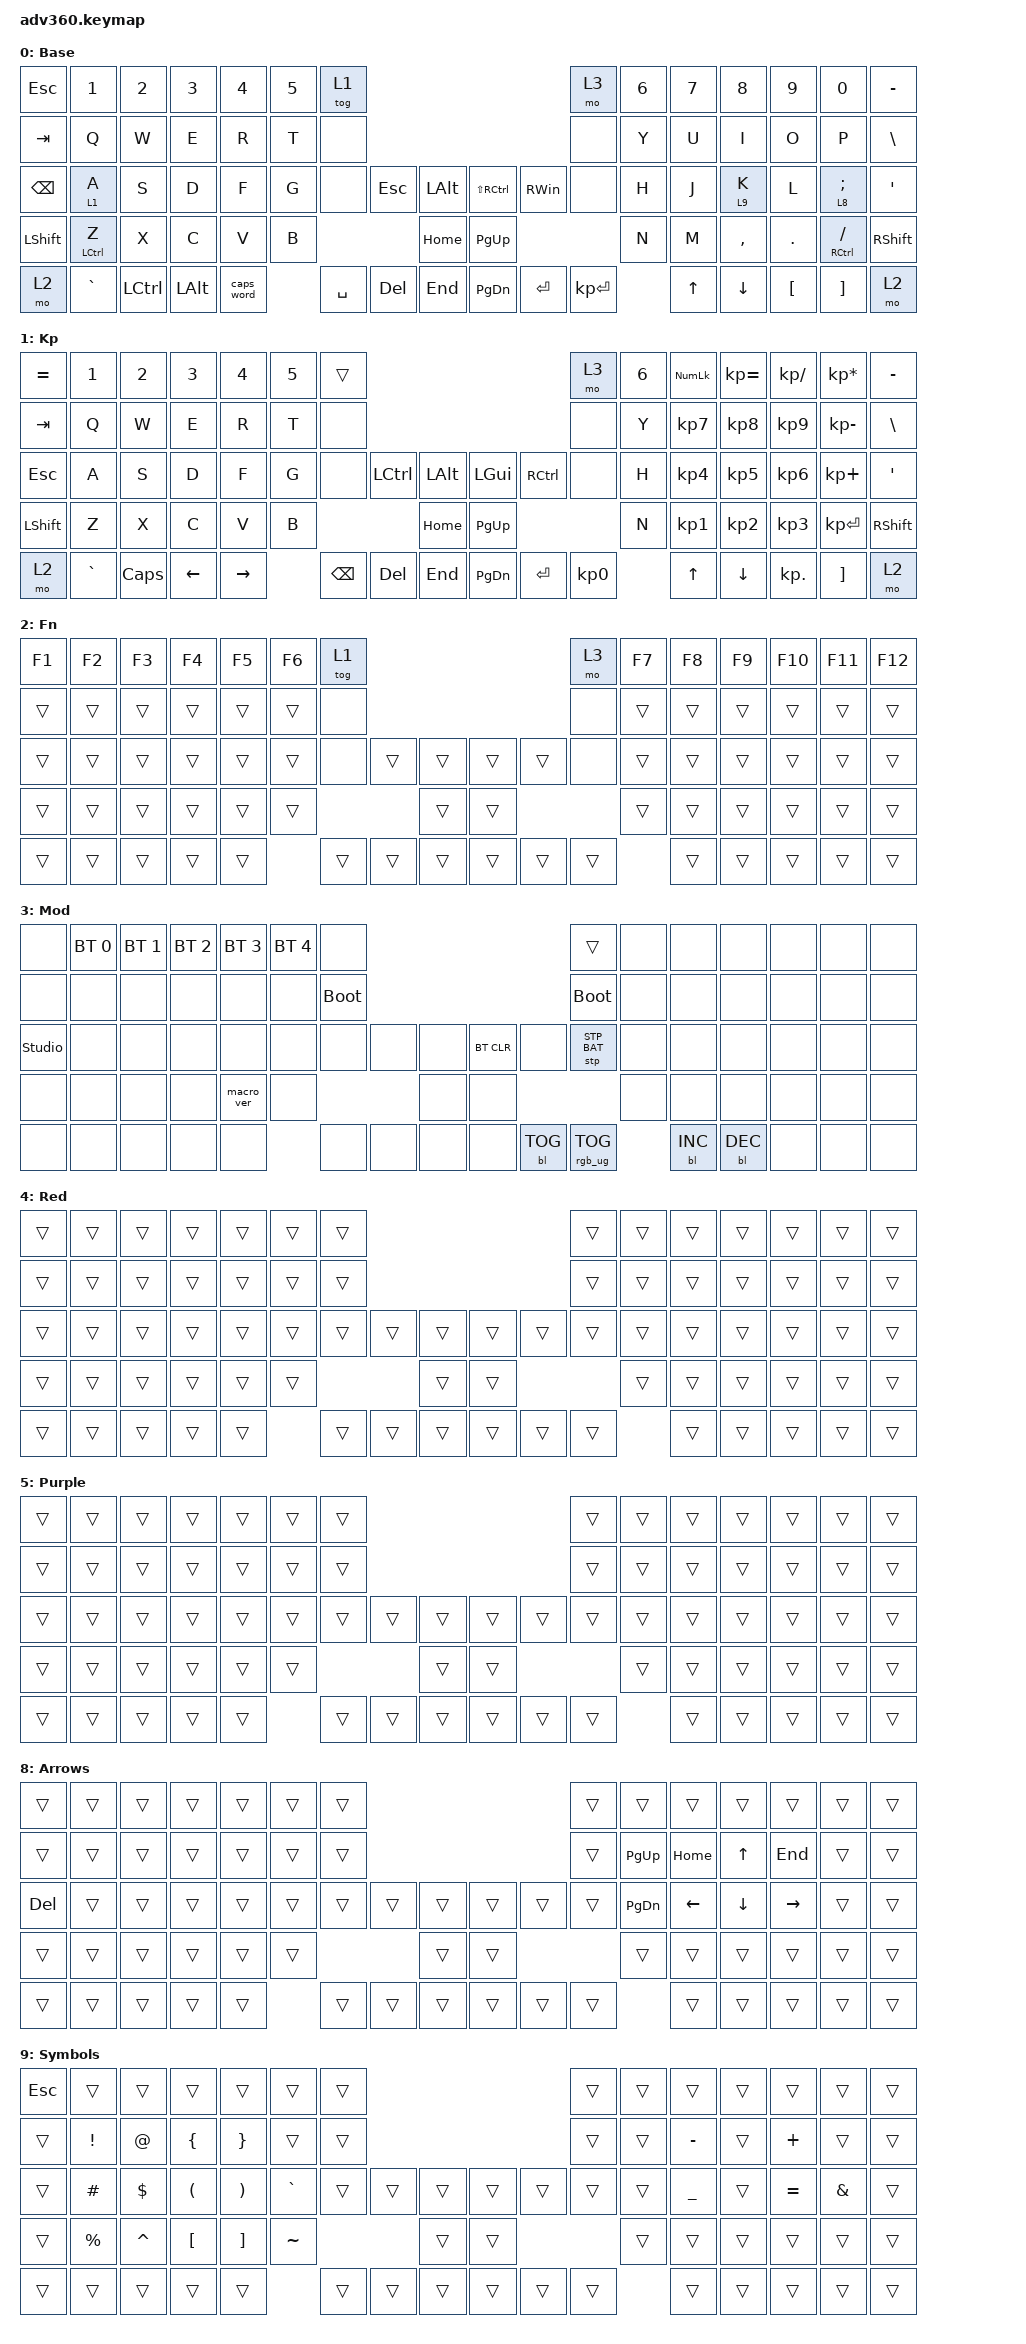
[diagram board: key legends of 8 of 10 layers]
#include <dt-bindings/zmk/stp.h>
#include <behaviors.dtsi>
#include <dt-bindings/zmk/backlight.h>
#include <dt-bindings/zmk/bt.h>
#include <dt-bindings/zmk/keys.h>
#include <dt-bindings/zmk/rgb.h>

/ {
    behaviors {
        #include "macros.dtsi"
      #include "version.dtsi"

        hm: homerow_mods {
            compatible = "zmk,behavior-hold-tap";
            label = "HOMEROW_MODS";
            #binding-cells = <2>;
            tapping-term-ms = <200>;
            quick_tap_ms = <175>;
            flavor = "tap-preferred";
            bindings = <&mo>, <&kp>;
        };

        tap_and_hold: tap_and_hold {
            compatible = "zmk,behavior-hold-tap";
            label = "TAP_AND_HOLD";
            bindings = <&kp>, <&kp>;

            #binding-cells = <2>;
            tapping-term-ms = <200>;
            flavor = "tap-preferred";
        };
    };

    keymap {
        compatible = "zmk,keymap";

        default_layer {
            display-name = "Base";
            bindings = <
&kp ESCAPE     &kp N1                        &kp N2            &kp N3        &kp N4      &kp N5  &tog 1                                                                     &mo 3         &kp N6  &kp N7  &kp N8     &kp N9    &kp N0                            &kp MINUS
&kp TAB        &kp Q                         &kp W             &kp E         &kp R       &kp T   &none                                                                      &none         &kp Y   &kp U   &kp I      &kp O     &kp P                             &kp BSLH
&kp BACKSPACE  &hm 1 A                       &kp S             &kp D         &kp F       &kp G   &none      &kp ESCAPE  &kp LALT      &kp LS(RIGHT_CONTROL)  &kp RIGHT_WIN  &none         &kp H   &kp J   &hm 9 K    &kp L     &hm 8 SEMICOLON                   &kp SQT
&kp LSHFT      &tap_and_hold LEFT_CONTROL Z  &kp X             &kp C         &kp V       &kp B                          &kp HOME      &kp PG_UP                                           &kp N   &kp M   &kp COMMA  &kp DOT   &tap_and_hold RIGHT_CONTROL FSLH  &kp RSHFT
&mo 2          &kp GRAVE                     &kp LEFT_CONTROL  &kp LEFT_ALT  &caps_word          &kp SPACE  &kp DEL     &kp END       &kp PG_DN              &kp ENTER      &kp KP_ENTER          &kp UP  &kp DOWN   &kp LBKT  &kp RBKT                          &mo 2
            >;
        };

        keypad {
            display-name = "Kp";
            bindings = <
&kp EQUAL  &kp N1     &kp N2    &kp N3    &kp N4     &kp N5  &trans                                                   &mo 3      &kp N6  &kp KP_NUM  &kp KP_EQUAL  &kp KP_DIVIDE  &kp KP_MULTIPLY  &kp MINUS
&kp TAB    &kp Q      &kp W     &kp E     &kp R      &kp T   &none                                                    &none      &kp Y   &kp KP_N7   &kp KP_N8     &kp KP_N9      &kp KP_MINUS     &kp BSLH
&kp ESC    &kp A      &kp S     &kp D     &kp F      &kp G   &none     &kp LCTRL  &kp LALT      &kp LGUI   &kp RCTRL  &none      &kp H   &kp KP_N4   &kp KP_N5     &kp KP_N6      &kp KP_PLUS      &kp SQT
&kp LSHFT  &kp Z      &kp X     &kp C     &kp V      &kp B                        &kp HOME      &kp PG_UP                        &kp N   &kp KP_N1   &kp KP_N2     &kp KP_N3      &kp KP_ENTER     &kp RSHFT
&mo 2      &kp GRAVE  &kp CAPS  &kp LEFT  &kp RIGHT          &kp BSPC  &kp DEL    &kp END       &kp PG_DN  &kp ENTER  &kp KP_N0          &kp UP      &kp DOWN      &kp KP_DOT     &kp RBKT         &mo 2
            >;
        };

        fn {
            display-name = "Fn";
            bindings = <
&kp F1  &kp F2  &kp F3  &kp F4  &kp F5  &kp F6  &tog 1                                      &mo 3   &kp F7  &kp F8  &kp F9  &kp F10  &kp F11  &kp F12
&trans  &trans  &trans  &trans  &trans  &trans  &none                                       &none   &trans  &trans  &trans  &trans   &trans   &trans
&trans  &trans  &trans  &trans  &trans  &trans  &none   &trans  &trans      &trans  &trans  &none   &trans  &trans  &trans  &trans   &trans   &trans
&trans  &trans  &trans  &trans  &trans  &trans                  &trans      &trans                  &trans  &trans  &trans  &trans   &trans   &trans
&trans  &trans  &trans  &trans  &trans          &trans  &trans  &trans      &trans  &trans  &trans          &trans  &trans  &trans   &trans   &trans
            >;
        };

        mod {
            display-name = "Mod";
            bindings = <
&none           &bt BT_SEL 0  &bt BT_SEL 1  &bt BT_SEL 2  &bt BT_SEL 3  &bt BT_SEL 4  &none                                                  &trans           &none  &none       &none       &none  &none  &none
&none           &none         &none         &none         &none         &none         &bootloader                                            &bootloader      &none  &none       &none       &none  &none  &none
&studio_unlock  &none         &none         &none         &none         &none         &none        &none  &none      &bt BT_CLR  &none       &stp STP_BAT     &none  &none       &none       &none  &none  &none
&none           &none         &none         &none         &macro_ver    &none                             &none      &none                                    &none  &none       &none       &none  &none  &none
&none           &none         &none         &none         &none                       &none        &none  &none      &none       &bl BL_TOG  &rgb_ug RGB_TOG         &bl BL_INC  &bl BL_DEC  &none  &none  &none
            >;
        };

        extra1 {
            display-name = "Red";
            bindings = <
&trans  &trans  &trans  &trans  &trans  &trans  &trans                                      &trans  &trans  &trans  &trans  &trans  &trans  &trans
&trans  &trans  &trans  &trans  &trans  &trans  &trans                                      &trans  &trans  &trans  &trans  &trans  &trans  &trans
&trans  &trans  &trans  &trans  &trans  &trans  &trans  &trans  &trans      &trans  &trans  &trans  &trans  &trans  &trans  &trans  &trans  &trans
&trans  &trans  &trans  &trans  &trans  &trans                  &trans      &trans                  &trans  &trans  &trans  &trans  &trans  &trans
&trans  &trans  &trans  &trans  &trans          &trans  &trans  &trans      &trans  &trans  &trans          &trans  &trans  &trans  &trans  &trans
            >;
        };

        extra2 {
            display-name = "Purple";
            bindings = <
&trans  &trans  &trans  &trans  &trans  &trans  &trans                                      &trans  &trans  &trans  &trans  &trans  &trans  &trans
&trans  &trans  &trans  &trans  &trans  &trans  &trans                                      &trans  &trans  &trans  &trans  &trans  &trans  &trans
&trans  &trans  &trans  &trans  &trans  &trans  &trans  &trans  &trans      &trans  &trans  &trans  &trans  &trans  &trans  &trans  &trans  &trans
&trans  &trans  &trans  &trans  &trans  &trans                  &trans      &trans                  &trans  &trans  &trans  &trans  &trans  &trans
&trans  &trans  &trans  &trans  &trans          &trans  &trans  &trans      &trans  &trans  &trans          &trans  &trans  &trans  &trans  &trans
            >;
        };

        extra3 {
            display-name = "Cyan";
            bindings = <
&trans  &trans  &trans  &trans  &trans  &trans  &trans                                      &trans  &trans  &trans  &trans  &trans  &trans  &trans
&trans  &trans  &trans  &trans  &trans  &trans  &trans                                      &trans  &trans  &trans  &trans  &trans  &trans  &trans
&trans  &trans  &trans  &trans  &trans  &trans  &trans  &trans  &trans      &trans  &trans  &trans  &trans  &trans  &trans  &trans  &trans  &trans
&trans  &trans  &trans  &trans  &trans  &trans                  &trans      &trans                  &trans  &trans  &trans  &trans  &trans  &trans
&trans  &trans  &trans  &trans  &trans          &trans  &trans  &trans      &trans  &trans  &trans          &trans  &trans  &trans  &trans
            >;
        };

        extra4 {
            display-name = "Yellow";
            bindings = <
&trans  &trans  &trans  &trans  &trans  &trans  &trans                                      &trans  &trans  &trans  &trans  &trans  &trans  &trans
&trans  &trans  &trans  &trans  &trans  &trans  &trans                                      &trans  &trans  &trans  &trans  &trans  &trans  &trans
&trans  &trans  &trans  &trans  &trans  &trans  &trans  &trans  &trans      &trans  &trans  &trans  &trans  &trans  &trans  &trans  &trans  &trans
&trans  &trans  &trans  &trans  &trans  &trans                  &trans      &trans                  &trans  &trans  &trans  &trans  &trans  &trans
&trans  &trans  &trans  &trans  &trans          &trans  &trans  &trans      &trans  &trans  &trans          &trans  &trans  &trans
            >;
        };

        Arrows {
            bindings = <
&trans   &trans  &trans  &trans  &trans  &trans  &trans                                      &trans  &trans         &trans          &trans          &trans           &trans  &trans
&trans   &trans  &trans  &trans  &trans  &trans  &trans                                      &trans  &kp PAGE_UP    &kp HOME        &kp UP_ARROW    &kp END          &trans  &trans
&kp DEL  &trans  &trans  &trans  &trans  &trans  &trans  &trans  &trans      &trans  &trans  &trans  &kp PAGE_DOWN  &kp LEFT_ARROW  &kp DOWN_ARROW  &kp RIGHT_ARROW  &trans  &trans
&trans   &trans  &trans  &trans  &trans  &trans                  &trans      &trans                  &trans         &trans          &trans          &trans           &trans  &trans
&trans   &trans  &trans  &trans  &trans          &trans  &trans  &trans      &trans  &trans  &trans                 &trans          &trans          &trans           &trans  &trans
            >;
        };

        Symbols {
            bindings = <
&kp ESCAPE  &trans           &trans      &trans                &trans                 &trans     &trans                                      &trans  &trans  &trans     &trans  &trans     &trans         &trans
&trans      &kp EXCLAMATION  &kp AT      &kp LEFT_BRACE        &kp RIGHT_BRACE        &trans     &trans                                      &trans  &trans  &kp MINUS  &trans  &kp PLUS   &trans         &trans
&trans      &kp POUND        &kp DOLLAR  &kp LEFT_PARENTHESIS  &kp RIGHT_PARENTHESIS  &kp GRAVE  &trans  &trans  &trans      &trans  &trans  &trans  &trans  &kp UNDER  &trans  &kp EQUAL  &kp AMPERSAND  &trans
&trans      &kp PERCENT      &kp CARET   &kp LEFT_BRACKET      &kp RIGHT_BRACKET      &kp TILDE                  &trans      &trans                  &trans  &trans     &trans  &trans     &trans         &trans
&trans      &trans           &trans      &trans                &trans                            &trans  &trans  &trans      &trans  &trans  &trans          &trans     &trans  &trans     &trans         &trans
            >;
        };
    };
};
